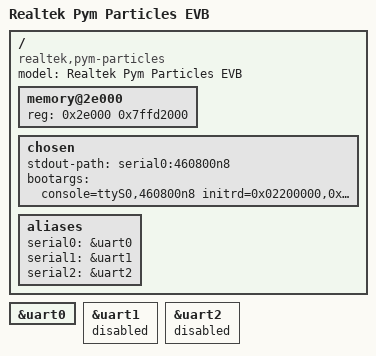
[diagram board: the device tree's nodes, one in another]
// SPDX-License-Identifier: (GPL-2.0-or-later OR BSD-2-Clause)
/*
 * Copyright (c) 2019-2020 Realtek Semiconductor Corp.
 */

/dts-v1/;

#include "rtd1319.dtsi"

/ {
	compatible = "realtek,pym-particles", "realtek,rtd1319";
	model = "Realtek Pym Particles EVB";

	memory@2e000 {
		device_type = "memory";
		reg = <0x2e000 0x7ffd2000>; /* boot ROM to 1 GiB or 2 GiB */
	};

	chosen {
		stdout-path = "serial0:460800n8";
		bootargs = "console=ttyS0,460800n8 initrd=0x02200000,0x00c00000";
	};

	aliases {
		serial0 = &uart0;
		serial1 = &uart1;
		serial2 = &uart2;
	};
};

/* debug console (J1) */
&uart0 {
	status = "okay";
};

/* M.2 slots (CON2, CON8) and J14 */
&uart1 {
	status = "disabled";
};

/* GPIO connector (T1) */
&uart2 {
	status = "disabled";
};
